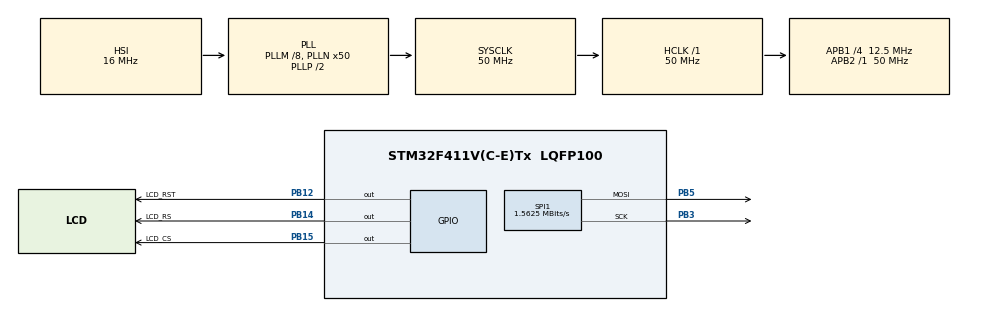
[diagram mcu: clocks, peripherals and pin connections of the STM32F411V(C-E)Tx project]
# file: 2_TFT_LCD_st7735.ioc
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Mcu.Family=STM32F4
Mcu.Name=STM32F411V(C-E)Tx
Mcu.Package=LQFP100
NVIC.PriorityGroup=NVIC_PRIORITYGROUP_0
PB12.GPIO_Label=LCD_RST
PB12.Signal=GPIO_Output
PB14.GPIO_Label=LCD_RS
PB14.Signal=GPIO_Output
PB15.GPIO_Label=LCD_CS
PB15.Signal=GPIO_Output
PB3.Mode=TX_Only_Simplex_Unidirect_Master
PB3.Signal=SPI1_SCK
PB5.Mode=TX_Only_Simplex_Unidirect_Master
PB5.Signal=SPI1_MOSI
ProjectManager.HeapSize=0x200
ProjectManager.StackSize=0x400
ProjectManager.TargetToolchain=STM32CubeIDE
RCC.48MHZClocksFreq_Value=12500000
RCC.AHBFreq_Value=50000000
RCC.APB1CLKDivider=RCC_HCLK_DIV4
RCC.APB1Freq_Value=12500000
RCC.APB1TimFreq_Value=25000000
RCC.APB2Freq_Value=50000000
RCC.APB2TimFreq_Value=50000000
RCC.CortexFreq_Value=50000000
RCC.HCLKFreq_Value=50000000
RCC.HSE_VALUE=8000000
RCC.HSI_VALUE=16000000
RCC.LSE_VALUE=32768
RCC.PLLI2SM=5
RCC.PLLI2SN=200
RCC.PLLM=8
RCC.PLLN=50
RCC.PLLQ=8
RCC.SYSCLKFreq_VALUE=50000000
RCC.SYSCLKSource=RCC_SYSCLKSOURCE_PLLCLK
RCC.VCOOutputFreq_Value=100000000
SPI1.BaudRatePrescaler=SPI_BAUDRATEPRESCALER_32
SPI1.CalculateBaudRate=1.5625 MBits/s
SPI1.Direction=SPI_DIRECTION_2LINES
SPI1.Mode=SPI_MODE_MASTER
SPI1.VirtualType=VM_MASTER
board=STM32F411E-DISCO

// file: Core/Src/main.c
/* USER CODE BEGIN Header */
/**
  ******************************************************************************
  * @file           : main.c
  * @brief          : Main program body
  ******************************************************************************
  * @attention
  *
  * Copyright (c) 2022 STMicroelectronics.
  * All rights reserved.
  *
  * This software is licensed under terms that can be found in the LICENSE file
  * in the root directory of this software component.
  * If no LICENSE file comes with this software, it is provided AS-IS.
  *
  ******************************************************************************
  */
/* USER CODE END Header */
#include "main.h"
#include "spi.h"
#include "gpio.h"

/* USER CODE BEGIN Includes */
#include "st7735.h"
#include "fonts.h"
#include "image_GUI.h"
/* USER CODE END Includes */

/* USER CODE BEGIN PD */
#define YMAX 5000
#define YMIN 0
/* USER CODE END PD */

void SystemClock_Config(void);

int main(void)
{

  /* MCU Configuration--------------------------------------------------------*/

  /* Reset of all peripherals, Initializes the Flash interface and the Systick. */
  HAL_Init();

  /* Configure the system clock */
  SystemClock_Config();

  /* Initialize all configured peripherals */
  MX_GPIO_Init();
  MX_SPI1_Init();
  /* USER CODE BEGIN 2 */
  ST7735_Init();

  ST7735_FillScreen(ST7735_WHITE);

//    HAL_Delay(1000);
//  ST7735_FillScreen(ST7735_RED);
//  HAL_Delay(1000);
//  ST7735_FillScreen(ST7735_GREEN);
//  HAL_Delay(1000);
//  ST7735_FillScreen(ST7735_BLUE);
//  HAL_Delay(1000);

//  ST7735_DrawImage(10,30,40,40,gImage_qq);
//  ST7735_DrawImage(5,5,120,120,gImage_jpeg_test_120x120);
//  HAL_Delay(1000);
//  scrolling();
//  ST7735_DrawImage(5,5,96,100,gImage_ST_logo_100x100);
//  HAL_Delay(1000);

  ST7735_WriteString(1,2,"2 Hello", Font_8x9, ST7735_RED, ST7735_RED);
  ST7735_WriteString(1,4,"2 Hello", Font_24x15, ST7735_RED, ST7735_RED);

  HAL_Delay(100);

  /* USER CODE END 2 */

  /* Infinite loop */
  while (1)
  {
	  HAL_Delay(100);
  }
}

void SystemClock_Config(void)
{
  RCC_OscInitTypeDef RCC_OscInitStruct = {0};
  RCC_ClkInitTypeDef RCC_ClkInitStruct = {0};

  /** Configure the main internal regulator output voltage
  */
  __HAL_RCC_PWR_CLK_ENABLE();
  __HAL_PWR_VOLTAGESCALING_CONFIG(PWR_REGULATOR_VOLTAGE_SCALE1);

  /** Initializes the RCC Oscillators according to the specified parameters
  * in the RCC_OscInitTypeDef structure.
  */
  RCC_OscInitStruct.OscillatorType = RCC_OSCILLATORTYPE_HSI;
  RCC_OscInitStruct.HSIState = RCC_HSI_ON;
  RCC_OscInitStruct.HSICalibrationValue = RCC_HSICALIBRATION_DEFAULT;
  RCC_OscInitStruct.PLL.PLLState = RCC_PLL_ON;
  RCC_OscInitStruct.PLL.PLLSource = RCC_PLLSOURCE_HSI;
  RCC_OscInitStruct.PLL.PLLM = 8;
  RCC_OscInitStruct.PLL.PLLN = 50;
  RCC_OscInitStruct.PLL.PLLP = RCC_PLLP_DIV2;
  RCC_OscInitStruct.PLL.PLLQ = 8;
  if (HAL_RCC_OscConfig(&RCC_OscInitStruct) != HAL_OK)
  {
    Error_Handler();
  }

  /** Initializes the CPU, AHB and APB buses clocks
  */
  RCC_ClkInitStruct.ClockType = RCC_CLOCKTYPE_HCLK|RCC_CLOCKTYPE_SYSCLK
                              |RCC_CLOCKTYPE_PCLK1|RCC_CLOCKTYPE_PCLK2;
  RCC_ClkInitStruct.SYSCLKSource = RCC_SYSCLKSOURCE_PLLCLK;
  RCC_ClkInitStruct.AHBCLKDivider = RCC_SYSCLK_DIV1;
  RCC_ClkInitStruct.APB1CLKDivider = RCC_HCLK_DIV4;
  RCC_ClkInitStruct.APB2CLKDivider = RCC_HCLK_DIV1;

  if (HAL_RCC_ClockConfig(&RCC_ClkInitStruct, FLASH_LATENCY_1) != HAL_OK)
  {
    Error_Handler();
  }
}

void Error_Handler(void)
{
  __disable_irq();
  while (1)
  {
  }
}
